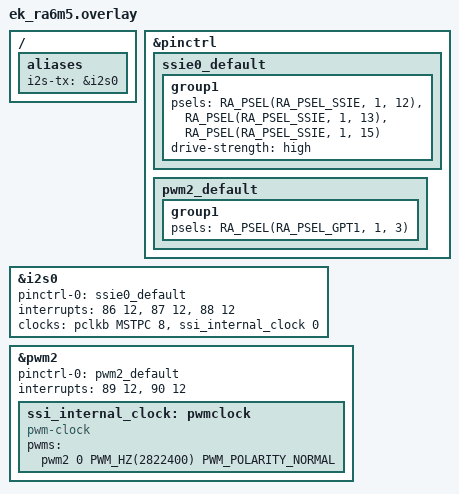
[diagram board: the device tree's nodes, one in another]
/*
 * Copyright (c) 2026 Renesas Electronics Corporation
 *
 * SPDX-License-Identifier: Apache-2.0
 */

#include <zephyr/dt-bindings/pwm/pwm.h>

/*
 * No wiring needed. To check the output, probe these i2s0 pins:
 *   SSI_BCK: P112, SSI_LRCK: P113, SSI_DATA: P115
 */

/ {
	aliases {
		i2s-tx = &i2s0;
	};
};

&pinctrl {
	ssie0_default: ssie0_default {
		group1 {
			/* SSI_BCK SSI_LRCK SSI_TX */
			psels = <RA_PSEL(RA_PSEL_SSIE, 1, 12)>,
				<RA_PSEL(RA_PSEL_SSIE, 1, 13)>,
				<RA_PSEL(RA_PSEL_SSIE, 1, 15)>;
			drive-strength = "high";
		};
	};

	pwm2_default: pwm2_default {
		group1 {
			/* GTIOC2A */
			psels = <RA_PSEL(RA_PSEL_GPT1, 1, 3)>;
		};
	};
};

&i2s0 {
	pinctrl-0 = <&ssie0_default>;
	pinctrl-names = "default";
	interrupts = <86 12>, <87 12>, <88 12>;
	interrupt-names = "ssi_txi", "ssi_rxi", "ssi_if";
	clocks = <&pclkb MSTPC 8>, <&ssi_internal_clock 0>;
	clock-names = "pclk", "audio-clock";
	status = "okay";
};

&pwm2 {
	pinctrl-0 = <&pwm2_default>;
	pinctrl-names = "default";
	interrupts = <89 12>, <90 12>;
	interrupt-names = "gtioca", "overflow";
	status = "okay";

	ssi_internal_clock: pwmclock {
		compatible = "pwm-clock";
		#clock-cells = <1>;
		pwms = <&pwm2 0 PWM_HZ(2822400) PWM_POLARITY_NORMAL>;
		status = "okay";
	};
};
